# STM32U585 register map
File version: 1.4
CPU: CM33 r0p1, little endian, MPU, FPU, 4 interrupt priority bits
Registers are 32-bit, read-write, reset 0x0 unless marked. A register's access mark holds for its fields unless they carry their own. Offsets are from the block's base; [hi:lo] are bit positions; {n}, {i} and the like mark numbered series; 'fields as' and 'values as' point back to an identical list.

## RCC (part 3 of 3) — Reset and clock control
Base 0x46020C00
Same registers: SEC_RCC 0x56020C00
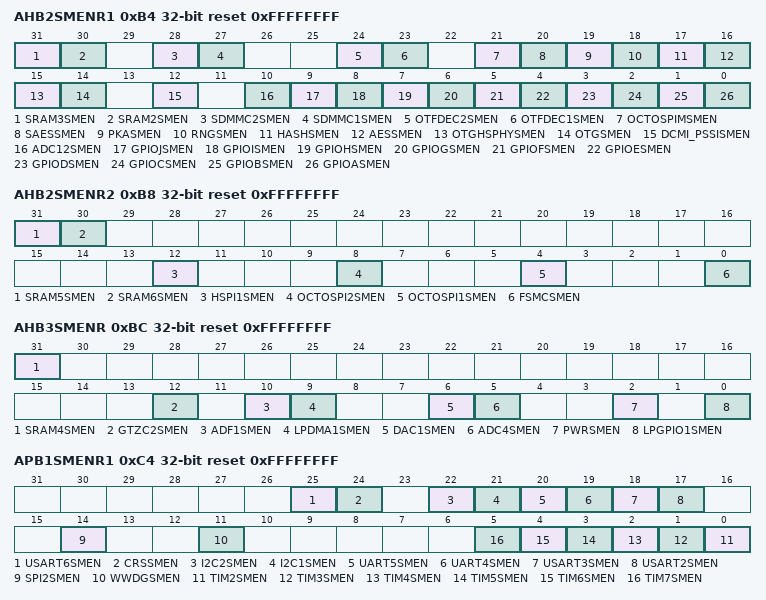
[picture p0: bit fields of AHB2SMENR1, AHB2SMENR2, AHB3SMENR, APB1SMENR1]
0xB4 AHB2SMENR1 reset 0xFFFFFFFF — RCC AHB2 peripheral clock enable in Sleep and Stop modes register 1
  [all] fields
    0=Disabled (Peripheral clocks disabled by the clock gating during Sleep and Stop modes); 1=Enabled (Peripheral clocks enabled by the clock gating during Sleep and Stop modes)
  [31] SRAM3SMEN — SRAM3 clock enable during Sleep and Stop modes This bit is set and cleared by software. Note: This bit is only available on some devices in the STM32U5 Series. Refer to the device datasheet for availability of its associated peripheral. If not present, consider this bit as reserved and keep it at reset value.
  [30] SRAM2SMEN — SRAM2 clock enable during Sleep and Stop modes This bit is set and cleared by software.
  [28] SDMMC2SMEN — SDMMC2 clock enable during Sleep and Stop modes This bit is set and cleared by software. Note: This bit is only available on some devices in the STM32U5 Series. Refer to the device datasheet for availability of its associated peripheral. If not present, consider this bit as reserved and keep it at reset value.
  [27] SDMMC1SMEN — SDMMC1 clock enable during Sleep and Stop modes This bit is set and cleared by software.
  [24] OTFDEC2SMEN — OTFDEC2 clock enable during Sleep and Stop modes This bit is set and cleared by software. Note: This bit is only available on some devices in the STM32U5 Series. Refer to the device datasheet for availability of its associated peripheral. If not present, consider this bit as reserved and keep it at reset value.
  [23] OTFDEC1SMEN — OTFDEC1 clock enable during Sleep and Stop modes This bit is set and cleared by software. Note: This bit is only available on some devices in the STM32U5 Series. Refer to the device datasheet for availability of its associated peripheral. If not present, consider this bit as reserved and keep it at reset value.
  [21] OCTOSPIMSMEN — OCTOSPIM clock enable during Sleep and Stop modes This bit is set and cleared by software. Note: This bit is only available on some devices in the STM32U5 Series. Refer to the device datasheet for availability of its associated peripheral. If not present, consider this bit as reserved and keep it at reset value.
  [20] SAESSMEN — SAES accelerator clock enable during Sleep and Stop modes This bit is set and cleared by software. Note: This bit is only available on some devices in the STM32U5 Series. Refer to the device datasheet for availability of its associated peripheral. If not present, consider this bit as reserved and keep it at reset value.
  [19] PKASMEN — PKA clock enable during Sleep and Stop modes This bit is set and cleared by software. Note: This bit is only available on some devices in the STM32U5 Series. Refer to the device datasheet for availability of its associated peripheral. If not present, consider this bit as reserved and keep it at reset value.
  [18] RNGSMEN — RNG clock enable during Sleep and Stop modes This bit is set and cleared by software.
  [17] HASHSMEN — HASH clock enable during Sleep and Stop modes This bit is set and cleared by software
  [16] AESSMEN — AES clock enable during Sleep and Stop modes This bit is set and cleared by software Note: This bit is only available on some devices in the STM32U5 Series. Refer to the device datasheet for availability of its associated peripheral. If not present, consider this bit as reserved and keep it at reset value.
  [15] OTGHSPHYSMEN — OTG_HS PHY clock enable during Sleep and Stop modes This bit is set and cleared by software Note: This bit is only available on some devices in the STM32U5 Series. Refer to the device datasheet for availability of its associated peripheral. If not present, consider this bit as reserved and keep it at reset value.
  [14] OTGSMEN — OTG_FS and OTG_HS clocks enable during Sleep and Stop modes This bit is set and cleared by software. Note: This bit is only available on some devices in the STM32U5 Series. Refer to the device datasheet for availability of its associated peripheral. If not present, consider this bit as reserved and keep it at reset value.
  [12] DCMI_PSSISMEN — DCMI and PSSI clock enable during Sleep and Stop modes This bit is set and cleared by software.
  [10] ADC12SMEN — ADC1 and ADC2 clock enable during Sleep and Stop modes This bit is set and cleared by software. Note: This bit impacts ADC1 in STM32U535/545/575/585 and ADC1/ADC2 in�STM32U59x/5Ax/5Fx/5Gx.
  [9] GPIOJSMEN — I/O port J clock enable during Sleep and Stop modes This bit is set and cleared by software. Note: This bit is only available on some devices in the STM32U5 Series. Refer to the device datasheet for availability of its associated peripheral. If not present, consider this bit as reserved and keep it at reset value.
  [8] GPIOISMEN — I/O port I clocks enable during Sleep and Stop modes This bit is set and cleared by software. Note: This bit is only available on some devices in the STM32U5 Series. Refer to the device datasheet for availability of its associated peripheral. If not present, consider this bit as reserved and keep it at reset value.
  [7] GPIOHSMEN — I/O port H clocks enable during Sleep and Stop modes This bit is set and cleared by software.
  [6] GPIOGSMEN — I/O port G clocks enable during Sleep and Stop modes This bit is set and cleared by software.
  [5] GPIOFSMEN — I/O port F clocks enable during Sleep and Stop modes This bit is set and cleared by software. Note: This bit is only available on some devices in the STM32U5 Series. Refer to the device datasheet for availability of its associated peripheral. If not present, consider this bit as reserved and keep it at reset value.
  [4] GPIOESMEN — I/O port E clocks enable during Sleep and Stop modes This bit is set and cleared by software.
  [3] GPIODSMEN — I/O port D clocks enable during Sleep and Stop modes This bit is set and cleared by software.
  [2] GPIOCSMEN — I/O port C clocks enable during Sleep and Stop modes This bit is set and cleared by software.
  [1] GPIOBSMEN — I/O port B clocks enable during Sleep and Stop modes This bit is set and cleared by software.
  [0] GPIOASMEN — I/O port A clocks enable during Sleep and Stop modes This bit is set and cleared by software.
0xB8 AHB2SMENR2 reset 0xFFFFFFFF — RCC AHB2 peripheral clock enable in Sleep and Stop modes register 2
  [all] fields
    values as the fields of AHB2SMENR1
  [31] SRAM5SMEN — SRAM5 clock enable during Sleep and Stop modes This bit is set and cleared by software. Note: This bit is only available on some devices in the STM32U5 Series. Refer to the device datasheet for availability of its associated peripheral. If not present, consider this bit as reserved and keep it at reset value.
  [30] SRAM6SMEN — SRAM6 clock enable during Sleep and Stop modes This bit is set and cleared by software. Note: This bit is only available on some devices in the STM32U5 Series. Refer to the device datasheet for availability of its associated peripheral. If not present, consider this bit as reserved and keep it at reset value.
  [12] HSPI1SMEN — HSPI1 clock enable during Sleep and Stop modes This bit is set and cleared by software. Note: This bit is only available on some devices in the STM32U5 Series. Refer to the device datasheet for availability of its associated peripheral. If not present, consider this bit as reserved and keep it at reset value.
  [8] OCTOSPI2SMEN — OCTOSPI2 clock enable during Sleep and Stop modes This bit is set and cleared by software. Note: This bit is only available on some devices in the STM32U5 Series. Refer to the device datasheet for availability of its associated peripheral. If not present, consider this bit as reserved and keep it at reset value.
  [4] OCTOSPI1SMEN — OCTOSPI1 clock enable during Sleep and Stop modes This bit is set and cleared by software.
  [0] FSMCSMEN — FSMC clock enable during Sleep and Stop modes This bit is set and cleared by software. Note: This bit is only available on some devices in the STM32U5 Series. Refer to the device datasheet for availability of its associated peripheral. If not present, consider this bit as reserved and keep it at reset value.
0xBC AHB3SMENR reset 0xFFFFFFFF — RCC AHB3 peripheral clock enable in Sleep and Stop modes register
  [all] fields
    values as the fields of AHB2SMENR1
  [31] SRAM4SMEN — SRAM4 clock enable during Sleep and Stop modes This bit is set and cleared by software.
  [12] GTZC2SMEN — GTZC2 clock enable during Sleep and Stop modes This bit is set and cleared by software.
  [10] ADF1SMEN — ADF1 clock enable during Sleep and Stop modes This bit is set and cleared by software. Note: This bit must be set to allow the peripheral to wake up from Stop modes.
  [9] LPDMA1SMEN — LPDMA1 clock enable during Sleep and Stop modes This bit is set and cleared by software. Note: This bit must be set to allow the peripheral to wake up from Stop modes.
  [6] DAC1SMEN — DAC1 clock enable during Sleep and Stop modes This bit is set and cleared by software. Note: This bit must be set to allow the peripheral to wake up from Stop modes.
  [5] ADC4SMEN — ADC4 clock enable during Sleep and Stop modes This bit is set and cleared by software. Note: This bit must be set to allow the peripheral to wake up from Stop modes.
  [2] PWRSMEN — PWR clock enable during Sleep and Stop modes This bit is set and cleared by software.
  [0] LPGPIO1SMEN — LPGPIO1 enable during Sleep and Stop modes This bit is set and cleared by software.
0xC4 APB1SMENR1 reset 0xFFFFFFFF — RCC APB1 peripheral clock enable in Sleep and Stop modes register 1
  [all] fields
    values as the fields of AHB2SMENR1
  [25] USART6SMEN — USART6 clock enable during Sleep and Stop modes This bit is set and cleared by software. Note: This bit must be set to allow the peripheral to wake up from Stop modes. Note: This bit is only available on some devices in the STM32U5 Series. Refer to the device datasheet for availability of its associated peripheral. If not present, consider this bit as reserved and keep it at reset value.
  [24] CRSSMEN — CRS clock enable during Sleep and Stop modes This bit is set and cleared by software.
  [22] I2C2SMEN — I2C2 clock enable during Sleep and Stop modes This bit is set and cleared by software. Note: This bit must be set to allow the peripheral to wake up from Stop modes.
  [21] I2C1SMEN — I2C1 clock enable during Sleep and Stop modes This bit is set and cleared by software. Note: This bit must be set to allow the peripheral to wake up from Stop modes.
  [20] UART5SMEN — UART5 clock enable during Sleep and Stop modes This bit is set and cleared by software. Note: This bit must be set to allow the peripheral to wake up from Stop modes.
  [19] UART4SMEN — UART4 clock enable during Sleep and Stop modes This bit is set and cleared by software. Note: This bit must be set to allow the peripheral to wake up from Stop modes.
  [18] USART3SMEN — USART3 clock enable during Sleep and Stop modes This bit is set and cleared by software. Note: This bit must be set to allow the peripheral to wake up from Stop modes.
  [17] USART2SMEN — USART2 clock enable during Sleep and Stop modes This bit is set and cleared by software. Note: This bit must be set to allow the peripheral to wake up from Stop modes. Note: This bit is only available on some devices in the STM32U5 Series. Refer to the device datasheet for availability of its associated peripheral. If not present, consider this bit as reserved and keep it at reset value.
  [14] SPI2SMEN — SPI2 clock enable during Sleep and Stop modes This bit is set and cleared by software. Note: This bit must be set to allow the peripheral to wake up from Stop modes.
  [11] WWDGSMEN — Window watchdog clock enable during Sleep and Stop modes This bit is set and cleared by software. It is forced to one by hardware when the hardware WWDG option is activated.
  [n-2] TIM{n}SMEN (n=2..7) — TIM{n} clock enable during Sleep and Stop modes This bit is set and cleared by software.
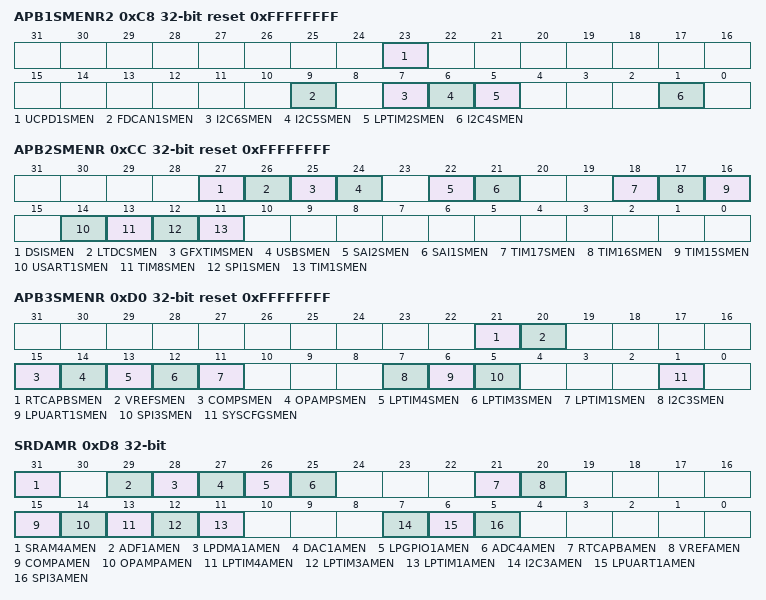
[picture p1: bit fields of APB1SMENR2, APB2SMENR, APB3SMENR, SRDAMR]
0xC8 APB1SMENR2 reset 0xFFFFFFFF — RCC APB1 peripheral clocks enable in Sleep and Stop modes register 2
  [all] fields
    values as the fields of AHB2SMENR1
  [23] UCPD1SMEN — UCPD1 clock enable during Sleep and Stop modes This bit is set and cleared by software. Note: This bit is only available on some devices in the STM32U5 Series. Refer to the device datasheet for availability of its associated peripheral. If not present, consider this bit as reserved and keep it at reset value.
  [9] FDCAN1SMEN — FDCAN1 clock enable during Sleep and Stop modes This bit is set and cleared by software.
  [7] I2C6SMEN — I2C6 clock enable during Sleep and Stop modes This bit is set and cleared by software Note: This bit must be set to allow the peripheral to wake up from Stop modes. Note: This bit is only available on some devices in the STM32U5 Series. Refer to the device datasheet for availability of its associated peripheral. If not present, consider this bit as reserved and keep it at reset value.
  [6] I2C5SMEN — I2C5 clock enable during Sleep and Stop modes This bit is set and cleared by software Note: This bit must be set to allow the peripheral to wake up from Stop modes. Note: This bit is only available on some devices in the STM32U5 Series. Refer to the device datasheet for availability of its associated peripheral. If not present, consider this bit as reserved and keep it at reset value.
  [5] LPTIM2SMEN — LPTIM2 clock enable during Sleep and Stop modes This bit is set and cleared by software. Note: This bit must be set to allow the peripheral to wake up from Stop modes.
  [1] I2C4SMEN — I2C4 clock enable during Sleep and Stop modes This bit is set and cleared by software Note: This bit must be set to allow the peripheral to wake up from Stop modes.
0xCC APB2SMENR reset 0xFFFFFFFF — RCC APB2 peripheral clocks enable in Sleep and Stop modes register
  [all] fields
    values as the fields of AHB2SMENR1
  [27] DSISMEN — DSI clock enable during Sleep and Stop modes This bit is set and cleared by software. Note: This bit is only available on some devices in the STM32U5 Series. Refer to the device datasheet for availability of its associated peripheral. If not present, consider this bit as reserved and keep it at reset value.
  [26] LTDCSMEN — LTDC clock enable during Sleep and Stop modes This bit is set and cleared by software. Note: This bit is only available on some devices in the STM32U5 Series. Refer to the device datasheet for availability of its associated peripheral. If not present, consider this bit as reserved and keep it at reset value.
  [25] GFXTIMSMEN — GFXTIM clock enable during Sleep and Stop modes This bit is set and cleared by software. Note: This bit is only available on some devices in the STM32U5 Series. Refer to the device datasheet for availability of its associated peripheral. If not present, consider this bit as reserved and keep it at reset value.
  [24] USBSMEN — USB clock enable during Sleep and Stop modes This bit is set and cleared by software. Note: This bit is only available on some devices in the STM32U5 Series. Refer to the device datasheet for availability of its associated peripheral. If not present, consider this bit as reserved and keep it at reset value.
  [22] SAI2SMEN — SAI2 clock enable during Sleep and Stop modes This bit is set and cleared by software. Note: This bit is only available on some devices in the STM32U5 Series.Refer to the device datasheet for availability of its associated peripheral. If not present, consider this bit as reserved and keep it at reset value.
  [21] SAI1SMEN — SAI1 clock enable during Sleep and Stop modes This bit is set and cleared by software.
  [18] TIM17SMEN — TIM17 clock enable during Sleep and Stop modes This bit is set and cleared by software.
  [17] TIM16SMEN — TIM16 clock enable during Sleep and Stop modes This bit is set and cleared by software.
  [16] TIM15SMEN — TIM15 clock enable during Sleep and Stop modes This bit is set and cleared by software.
  [14] USART1SMEN — USART1 clock enable during Sleep and Stop modes This bit is set and cleared by software. Note: This bit must be set to allow the peripheral to wake up from Stop modes.
  [13] TIM8SMEN — TIM8 clock enable during Sleep and Stop modes This bit is set and cleared by software.
  [12] SPI1SMEN — SPI1 clock enable during Sleep and Stop modes This bit is set and cleared by software. Note: This bit must be set to allow the peripheral to wake up from Stop modes.
  [11] TIM1SMEN — TIM1 clock enable during Sleep and Stop modes This bit is set and cleared by software.
0xD0 APB3SMENR reset 0xFFFFFFFF — RCC APB3 peripheral clock enable in Sleep and Stop modes register
  [all] fields
    values as the fields of AHB2SMENR1
  [21] RTCAPBSMEN — RTC and TAMP APB clock enable during Sleep and Stop modes This bit is set and cleared by software. Note: This bit must be set to allow the peripheral to wake up from Stop modes.
  [20] VREFSMEN — VREFBUF clock enable during Sleep and Stop modes This bit is set and cleared by software.
  [15] COMPSMEN — COMP clock enable during Sleep and Stop modes This bit is set and cleared by software.
  [14] OPAMPSMEN — OPAMP clock enable during Sleep and Stop modes This bit is set and cleared by software.
  [13] LPTIM4SMEN — LPTIM4 clock enable during Sleep and Stop modes This bit is set and cleared by software. Note: This bit must be set to allow the peripheral to wake up from Stop modes.
  [12] LPTIM3SMEN — LPTIM3 clock enable during Sleep and Stop modes This bit is set and cleared by software. Note: This bit must be set to allow the peripheral to wake up from Stop modes.
  [11] LPTIM1SMEN — LPTIM1 clock enable during Sleep and Stop modes This bit is set and cleared by software. Note: This bit must be set to allow the peripheral to wake up from Stop modes.
  [7] I2C3SMEN — I2C3 clock enable during Sleep and Stop modes This bit is set and cleared by software. Note: This bit must be set to allow the peripheral to wake up from Stop modes.
  [6] LPUART1SMEN — LPUART1 clock enable during Sleep and Stop modes This bit is set and cleared by software. Note: This bit must be set to allow the peripheral to wake up from Stop modes.
  [5] SPI3SMEN — SPI3 clock enable during Sleep and Stop modes This bit is set and cleared by software. Note: This bit must be set to allow the peripheral to wake up from Stop modes.
  [1] SYSCFGSMEN — SYSCFG clock enable during Sleep and Stop modes This bit is set and cleared by software.
0xD8 SRDAMR — RCC SmartRun domain peripheral autonomous mode register
  [all] fields
    0=Disabled (Peripheral autonomous mode disabled during Stop 0/1/2 mode); 1=Enabled (Peripheral autonomous mode enabled during Stop 0/1/2 mode)
  [31] SRAM4AMEN — SRAM4 autonomous mode enable in Stop 0/1/2 mode This bit is set and cleared by software.
  [29] ADF1AMEN — ADF1 autonomous mode enable in Stop 0/1/2 mode This bit is set and cleared by software. Note: This bit must be set to allow the peripheral to wake up from Stop modes.
  [28] LPDMA1AMEN — LPDMA1 autonomous mode enable in Stop 0/1/2 mode This bit is set and cleared by software. Note: This bit must be set to allow the peripheral to wake up from Stop modes.
  [27] DAC1AMEN — DAC1 autonomous mode enable in Stop 0/1/2 mode This bit is set and cleared by software. Note: This bit must be set to allow the peripheral to wake up from Stop modes.
  [26] LPGPIO1AMEN — LPGPIO1 autonomous mode enable in Stop 0/1/2 mode This bit is set and cleared by software.
  [25] ADC4AMEN — ADC4 autonomous mode enable in Stop 0/1/2 mode This bit is set and cleared by software. Note: This bit must be set to allow the peripheral to wake up from Stop modes.
  [21] RTCAPBAMEN — RTC and TAMP autonomous mode enable in Stop 0/1/2 mode This bit is set and cleared by software. Note: This bit must be set to allow the peripheral to wake up from Stop modes.
  [20] VREFAMEN — VREFBUF autonomous mode enable in Stop 0/1/2 mode This bit is set and cleared by software.
  [15] COMPAMEN — COMP autonomous mode enable in Stop 0/1/2 mode This bit is set and cleared by software.
  [14] OPAMPAMEN — OPAMP autonomous mode enable in Stop 0/1/2 mode This bit is set and cleared by software.
  [13] LPTIM4AMEN — LPTIM4 autonomous mode enable in Stop 0/1/2 mode This bit is set and cleared by software. Note: This bit must be set to allow the peripheral to wake up from Stop modes.
  [12] LPTIM3AMEN — LPTIM3 autonomous mode enable in Stop 0/1/2 mode This bit is set and cleared by software. Note: This bit must be set to allow the peripheral to wake up from Stop modes.
  [11] LPTIM1AMEN — LPTIM1 autonomous mode enable in Stop 0/1/2 mode This bit is set and cleared by software. Note: This bit must be set to allow the peripheral to wake up from Stop modes.
  [7] I2C3AMEN — I2C3 autonomous mode enable in Stop 0/1/2 mode This bit is set and cleared by software. Note: This bit must be set to allow the peripheral to wake up from Stop modes.
  [6] LPUART1AMEN — LPUART1 autonomous mode enable in Stop 0/1/2 mode This bit is set and cleared by software. Note: This bit must be set to allow the peripheral to wake up from Stop modes.
  [5] SPI3AMEN — SPI3 autonomous mode enable in Stop 0,1, 2 mode This bit is set and cleared by software. Note: This bit must be set to allow the peripheral to wake up from Stop modes.
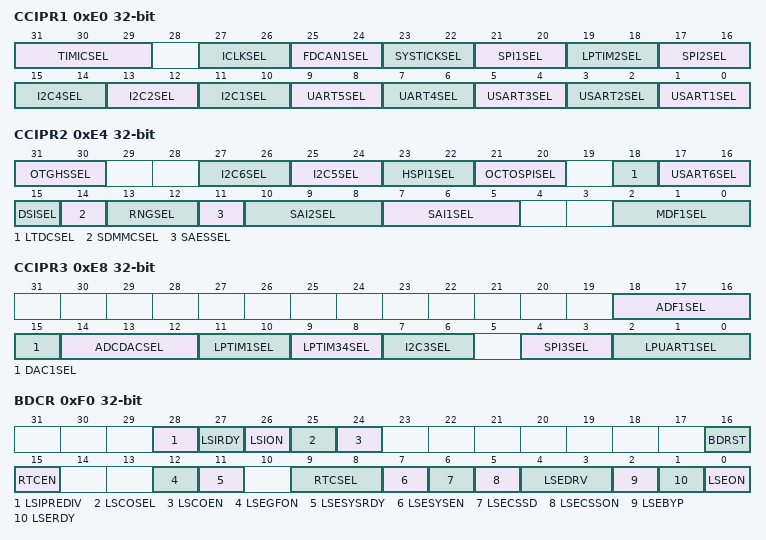
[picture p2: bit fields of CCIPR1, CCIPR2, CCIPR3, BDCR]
0xE0 CCIPR1 — RCC peripherals independent clock configuration register 1
  [31:29] TIMICSEL — Clock sources for TIM16,TIM17, and LPTIM2 internal input capture When TIMICSEL2 is set, the TIM16, TIM17, and LPTIM2 internal input capture can be connected either to HSI/256, MSI/4, or MSI/1024. Depending on TIMICSEL[1:0] value, MSI is either MSIK or MSIS. When TIMICSEL2 is cleared, the HSI, MSIK, and MSIS clock sources cannot be selected as�TIM16, TIM17, or LPTIM2 internal input capture. 0xx: HSI, MSIK and MSIS dividers disabled Note: The clock division must be disabled (TIMICSEL configured to 0xx) before selecting or changing a clock sources division.
    4=HsiMsisMsis (HSI/256, MSIS/1024 and MSIS/4 generated and can be selected by TIM16, TIM17, and LPTIM2 as internal input capture); 5=HsiMsisMsik (HSI/256, MSIS/1024 and MSIK/4 generated and can be selected by TIM16, TIM17, and LPTIM2 as internal input capture); 6=HsiMsikMsis (HSI/256, MSIK/1024 and MSIS/4 generated and can be selected by TIM16, TIM17, and LPTIM2 as internal input capture); 7=HsiMsikMsik (HSI/256, MSIK/1024 and MSIK/4 generated and can be selected by TIM16, TIM17, and LPTIM2 as internal input capture); other=Disabled (HSI, MSIK and MSIS dividers disabled)
  [27:26] ICLKSEL — Intermediate clock source selection These bits are used to select the clock source for the OTG_FS, the USB, and the SDMMC.
    0=HSI (HSI48 clock selected); 1=PLL2Q (PLL2 "Q" (pll2_q_ck) selected); 2=PLL1Q (PLL1 "Q" (pll1_q_ck) selected); 3=MSIK (MSIK clock selected)
  [25:24] FDCAN1SEL — FDCAN1 kernel clock source selection These bits are used to select the FDCAN1 kernel clock source.
    0=HSE (HSE clock selected); 1=PLL1Q (PLL1 "Q" (pll2_q_ck) selected); 2=PLL2P (PLL2 "P" (pll1_p_ck) selected)
  [23:22] SYSTICKSEL — SysTick clock source selection These bits are used to select the SysTick clock source. Note: When LSE or LSI is selected, the AHB frequency must be at least four times higher than the LSI or LSE frequency. In addition, a jitter up to one HCLK cycle is introduced, due to the LSE or LSI sampling with HCLK in the SysTick circuitry.
    0=HCLK_Div8 (HCLK/8 selected); 1=LSI (LSI selected); 2=LSE (LSE selected)
  [21:20] SPI1SEL — SPI1 kernel clock source selection These bits are used to select the SPI1 kernel clock source. Note: The SPI1 is functional in Stop 0 and Stop 1 mode only when the kernel clock is HSI16 or MSIK.
    0=PCLK (PCLKx selected); 1=SYSCLK (SYSCLK selected); 2=HSI16 (HSI16 selected); 3=MSIK (MSIK selected)
  [19:18] LPTIM2SEL — Low-power timer 2 kernel clock source selection These bits are used to select the LPTIM2 kernel clock source. Note: The LPTIM2 is functional in Stop 0 and Stop 1 mode only when the kernel clock is LSI, LSE or HSI16 if HSIKERON = 1.
    0=PCLK1 (PCLK1 selected); 1=LSI (LSI selected); 2=HSI16 (HSI16 selected); 3=MSIK (MSIK selected)
  [17:16] SPI2SEL — SPI2 kernel clock source selection These bits are used to select the SPI2 kernel clock source. Note: The SPI2 is functional in Stop 0 and Stop 1 mode only when the kernel clock is HSI16 or MSIK.
    values as SPI1SEL
  [15:14] I2C4SEL — I2C4 kernel clock source selection These bits are used to select the I2C4 kernel clock source. Note: The I2C4 is functional in Stop 0 and Stop 1 modes only when the kernel clock is HSI16�or MSIK.
    values as SPI1SEL
  [13:12] I2C2SEL — I2C2 kernel clock source selection These bits are used to select the I2C2 kernel clock source. Note: The I2C2 is functional in Stop 0 and Stop 1 mode sonly when the kernel clock is HSI16�or MSIK.
    values as SPI1SEL
  [11:10] I2C1SEL — I2C1 kernel clock source selection These bits are used to select the I2C1 kernel clock source. Note: The I2C1 is functional in Stop 0 and Stop 1 mode sonly when the kernel clock is HSI16�or MSIK.
    values as SPI1SEL
  [9:8] UART5SEL — UART5 kernel clock source selection These bits are used to select the UART5 kernel clock source. Note: The UART5 is functional in Stop 0 and Stop 1 modes only when the kernel clock is HSI16 or LSE.
    values as SPI1SEL
  [7:6] UART4SEL — UART4 kernel clock source selection These bits are used to select the UART4 kernel clock source. Note: The UART4 is functional in Stop 0 and Stop 1 modes only when the kernel clock is HSI16 or LSE.
    values as SPI1SEL
  [5:4] USART3SEL — USART3 kernel clock source selection These bits are used to select the USART3 kernel clock source. Note: The USART3 is functional in Stop 0 and Stop 1 modes only when the kernel clock is HSI16 or LSE.
    values as SPI1SEL
  [3:2] USART2SEL — USART2 kernel clock source selection These bits are used to select the USART2 kernel clock source. The USART2 is functional in Stop 0 and Stop 1 modes only when the kernel clock is HSI16 or LSE. Note: This bitfield is only available on some devices in the STM32U5 Series. Refer to the device datasheet for availability of its associated peripheral. If not present, consider this bitfield as reserved and keep it at reset value.
    values as SPI1SEL
  [1:0] USART1SEL — USART1 kernel clock source selection These bits are used to select the USART1 kernel clock source. Note: The USART1 is functional in Stop 0 and Stop 1 modes only when the kernel clock is HSI16 or LSE.
    values as SPI1SEL
0xE4 CCIPR2 — RCC peripherals independent clock configuration register 2
  [31:30] OTGHSSEL — OTG_HS PHY kernel clock source selection These bits are used to select the OTG_HS PHY kernel clock source. Note: This bitfield is only available on some devices in the STM32U5 Series. Refer to the device datasheet for availability of its associated peripheral. If not present, consider this bitfield as reserved and keep it at reset value.
    0=HSE (HSE selected); 1=PLL1P (PLL1 "Q" (pll1_q_ck) selected); 2=HSE2 (HSE/2 selected); 3=PLL1P_Div2 (PLL1 "P" divided by 2 (pll1_p_ck/2) selected)
  [27:26] I2C6SEL — I2C6 kernel clock source selection These bits are used to select the I2C6 kernel clock source. The I2C6 is functional in Stop 0 and Stop 1 modes only when the kernel clock is HSI16�or MSIK. Note: This bitfield is only available on some devices in the STM32U5 Series. Refer to the device datasheet for availability of its associated peripheral. If not present, consider this bitfield as reserved and keep it at reset value.
    0=PCLK1 (PCLK1 selected); 1=SYSCLK (SYSCLK selected); 2=HSI16 (HSI16 selected); 3=MSIK (MSIK selected)
  [25:24] I2C5SEL — I2C5 kernel clock source selection These bits are used to select the I2C5 kernel clock source. The I2C5 is functional in Stop 0 and Stop 1 modes only when the kernel clock is HSI16�or MSIK. Note: This bitfield is only available on some devices in the STM32U5 Series. Refer to the device datasheet for availability of its associated peripheral. If not present, consider this bitfield as reserved and keep it at reset value.
    values as I2C6SEL
  [23:22] HSPI1SEL — HSPI1 kernel clock source selection These bits are used to select the HSPI1 kernel clock source. Note: This bitfield is only available on some devices in the STM32U5 Series. Refer to the device datasheet for availability of its associated peripheral. If not present, consider this bitfield as reserved and keep it at reset value.
    0=SYSCLK (SYSCLK selected); 1=PLL1Q (PLL1 "Q" (pll1_q_ck) selected, can be up to 200 MHz); 2=PLL2Q (PLL2 "Q" (pll2_q_ck) selected, can be up to 200 MHz); 3=PLL3R (PLL3 "R" (pll3_r_ck) selected, can be up to 200 MHz)
  [21:20] OCTOSPISEL — OCTOSPI1 and OCTOSPI2 kernel clock source selection These bits are used to select the OCTOSPI1 and OCTOSPI2 kernel clock source.
    0=SYSCLK (SYSCLK selected); 1=MSIK (MSIK selected); 2=PLL1Q (PLL1 "Q" (pll1_q_ck) selected, can be up to 200 MHz); 3=PLL2Q (PLL2 "Q" (pll2_q_ck) selected, can be up to 200 MHz)
  [18] LTDCSEL — LTDC kernel clock source selection This bit is used to select the LTDC kernel clock source. Note: This bit is only available on some devices in the STM32U5 Series. Refer to the device datasheet for availability of its associated peripheral. If not present, consider this bit as reserved and keep it at reset value.
    0=PLL3R (PLL3 "R" (pll3_r_ck) selected); 1=PLL2R (PLL2 "R" (pll2_r_ck) selected)
  [17:16] USART6SEL — USART6 kernel clock source selection These bits are used to select the USART6 kernel clock source. The USART6 is functional in Stop 0 and Stop 1 modes only when the kernel clock is HSI16 or LSE. Note: This bitfield is only available on some devices in the STM32U5 Series. Refer to the device datasheet for availability of its associated peripheral. If not present, consider this bitfield as reserved and keep it at reset value.
    values as I2C6SEL
  [15] DSISEL — DSI kernel clock source selection This bit is used to select the DSI kernel clock source. This bit is only available on some devices in the STM32U5 Series. Refer to the device datasheet for availability of its associated peripheral. Note: If not present, consider this bit as reserved and keep it at reset value.
    0=PLL3P (PLL3 "P" (pll3_p_ck) selected); 1=DSI_PHY_PLL (DSI PHY PLL output selected)
  [14] SDMMCSEL — SDMMC1 and SDMMC2 kernel clock source selection This bit is used to select the SDMMC kernel clock source. It is recommended to change it only after reset and before enabling the SDMMC.
    0=ICLK (ICLK clock selected); 1=PLL1P (PLL1 "P" (pll1_p_ck) selected, in case higher than 48 MHz is needed (for SDR50 mode))
  [13:12] RNGSEL — RNG kernel clock source selection These bits are used to select the RNG kernel clock source.
    0=HSI48 (HSI48 clock selected); 1=HSI48_Div2 (HSI48 / 2 selected, can be used in range 4); 2=HSI16 (HSI16 selected)
  [11] SAESSEL — SAES kernel clock source selection This bit is used to select the SAES kernel clock source. Note: This bit is only available on some devices in the STM32U5 Series. Refer to the device datasheet for availability of its associated peripheral. If not present, consider this bit as reserved and keep it at reset value.
    0=SHSI (SHSI selected); 1=SHSI_Div2 (SHSI / 2 selected, can be used in range 4)
  [10:8] SAI2SEL — SAI2 kernel clock source selection These bits are used to select the SAI2 kernel clock source. others: reserved If the selected clock is the external clock and this clock is stopped, a switch to another clock is impossible. Note: This bitfield is only available on some devices in the STM32U5 Series. Refer to the device datasheet for availability of its associated peripheral. If not present, consider this bitfield as reserved and keep it at reset value.
    0=PLL2P (PLL2 "P" (pll2_p_ck) selected); 1=PLL3P (PLL3 "P" (pll3_p_ck) selected); 2=PLL1P (PLL1 "P" (pll1_p_ck) selected); 3=AUDIOCLK (input pin AUDIOCLK selected); 4=HSI16 (HSI16 clock selected)
  [7:5] SAI1SEL — SAI1 kernel clock source selection These bits are used to select the SAI1 kernel clock source. others: reserved Note: If the selected clock is the external clock and this clock is stopped, a switch to another clock is impossible.
    values as SAI2SEL
  [2:0] MDF1SEL — MDF1 kernel clock source selection These bits are used to select the MDF1 kernel clock source. others: reserved
    0=HCLK (HCLK selected); 1=PLL1P (PLL1 "P" (pll1_p_ck) selected); 2=PLL3Q (PLL3 "Q" (pll3_q_ck) selected); 3=AUDIOCLK (input pin AUDIOCLK selected); 4=MSIK (MSIK clock selected)
0xE8 CCIPR3 — RCC peripherals independent clock configuration register 3
  [18:16] ADF1SEL — ADF1 kernel clock source selection These bits are used to select the ADF1 kernel clock source. others: reserved Note: The ADF1 is functional in Stop 0, Stop 1, and Stop 2 modes only when the kernel clock is AUDIOCLK or MSIK.
    values as CCIPR2.MDF1SEL
  [15] DAC1SEL — DAC1 sample-and-hold clock source selection This bit is used to select the DAC1 sample-and-hold clock source.
    0=LSE (LSE selected); 1=LSI (LSI selected)
  [14:12] ADCDACSEL — ADC1, ADC2, ADC4 and DAC1 kernel clock source selection These bits are used to select the ADC1, ADC2, ADC4, and DAC1 kernel clock source. others: reserved Note: The ADC1, ADC2, ADC4, and DAC1 are functional in Stop 0, Stop 1, and Stop 2 modes only when the kernel clock is HSI16 or MSIK (only ADC4 and DAC1 are functional in�Stop 2 mode).
    0=HCLK (HCLK clock selected); 1=SYSCLK (SYSCLK selected); 2=PLL2R (PLL2 "R" (pll2_r_ck) selected); 3=HSE (HSE clock selected); 4=HSI16 (HSI16 clock selected); 5=MSIK (MSIK clock selected)
  [11:10] LPTIM1SEL — LPTIM1 kernel clock source selection These bits are used to select the LPTIM1 kernel clock source. Note: The LPTIM1 is functional in Stop 0, Stop 1, and Stop 2 modes only when the kernel clock is LSI, LSE, HSI16 with HSIKERON = 1, or MSIK with MSIKERON = 1.
    0=MSIK (MSIK clock selected); 1=LSI (LSI selected); 2=HSI16 (HSI16 selected); 3=LSE (LSE selected)
  [9:8] LPTIM34SEL — LPTIM3 and LPTIM4 kernel clock source selection These bits are used to select the LPTIM3 and LPTIM4 kernel clock source. Note: The LPTIM3 and LPTIM4 are functional in Stop 0, Stop 1, and Stop 2 modes only when the kernel clock is LSI, LSE, HSI16 with HSIKERON = 1, or MSIK with MSIKERON�=�1.
    0=MSIK (MSIK clock selected); 1=LSI (LSI selected); 2=HSI (HSI selected); 3=LSE (LSE selected)
  [7:6] I2C3SEL — I2C3 kernel clock source selection These bits are used to select the I2C3 kernel clock source. Note: The I2C3 is functional in Stop 0, Stop 1, and Stop 2 modes only when the kernel clock is HSI16 or MSIK.
    0=PCLK3 (PCLK3 selected); 1=SYSCLK (SYSCLK selected); 2=HSI16 (HSI16 selected); 3=MSIK (MSIK selected)
  [4:3] SPI3SEL — SPI3 kernel clock source selection These bits are used to select the SPI3 kernel clock source. Note: The SPI3 is functional in Stop 0, Stop 1, and Stop 2 modes only when the kernel clock is HSI16 or MSIK.
    values as I2C3SEL
  [2:0] LPUART1SEL — LPUART1 kernel clock source selection These bits are used to select the LPUART1 kernel clock source. others: reserved Note: The LPUART1 is functional in Stop 0, Stop 1, and Stop 2 modes only when the kernel clock is HSI16, LSE, or MSIK.
    0=PCLK3 (PCLK3 selected); 1=SYSCLK (SYSCLK selected); 2=HSI16 (HSI16 selected); 3=LSE (LSE selected); 4=MSIK (MSIK selected)
0xF0 BDCR access per field — RCC backup domain control register
  [28] LSIPREDIV rw — Low-speed clock divider configuration This bit is set and cleared by software to enable the LSI division. It can be written only when the LSI is disabled (LSION = 0 and LSIRDY = 0). If the LSI was previously enabled, it is necessary to wait for at least 60 μs after clearing LSION bit (synchronization time for LSI to be really disabled), before writing LSIPREDIV. The LSIPREDIV cannot be changed if the LSI is used by the IWDG or by the RTC.
    0=Div1 (LSI not divided); 1=Div128 (LSI divided by 128)
  [27] LSIRDY rw — LSI oscillator ready This bit is set and cleared by hardware to indicate when the LSI oscillator is stable. After�LSION is cleared, LSIRDY goes low after three internal low-speed oscillator clock cycles. This bit is set when the LSI is used by IWDG or RTC, even if LSION = 0.
    on read: 0=NotReady (LSI oscillator not ready); 1=Ready (LSI oscillator ready)
  [26] LSION rw — LSI oscillator enable This bit is set and cleared by software. The LSI oscillator is disabled 60��s maximum after the LSION bit is cleared.
    0=Disabled (LSI oscillator OFF); 1=Enabled (LSI oscillator ON)
  [25] LSCOSEL rw — Low-speed clock output selection This bit is set and cleared by software.
    0=LSI (LSI clock selected); 1=LSE (LSE clock selected)
  [24] LSCOEN rw — Low-speed clock output (LSCO) enable This bit is set and cleared by software.
    0=Disabled (LSCO disabled); 1=Enabled (LSCO enabled)
  [16] BDRST rw — Backup domain software reset This bit is set and cleared by software.
    0=NoReset (Reset not activated); 1=Reset the entire backup domain
  [15] RTCEN rw — RTC and TAMP clock enable This bit is set and cleared by software.
    0=Disabled (RTC and TAMP clock disabled); 1=Enabled (RTC and TAMP clock enabled)
  [12] LSEGFON rw — LSE clock glitch filter enable This bit is set and cleared by hardware to enable the LSE glitch filter. It can be written only when the LSE is disabled (LSEON = 0 and LSERDY = 0).
    0=Disabled (LSE glitch filter disabled); 1=Enabled (LSE glitch filter enabled)
  [11] LSESYSRDY ro — LSE system clock (LSESYS) ready This bit is set and cleared by hardware to indicate when the LSE system clock is stable.When LSESYSEN is set, this LSESYSRDY flag is set after two LSE clock cycles. The LSE clock must be already enabled and stable (LSEON and LSERDY are set). When the LSEON bit is cleared, LSERDY goes low after six external low-speed oscillator clock cycles.
    0=NotReady (LSESYS clock not ready); 1=Ready (LSESYS clock ready)
  [9:8] RTCSEL rw — RTC and TAMP clock source selection This bit is set by software to select the clock source for the RTC and TAMP. Once the RTC and TAMP clock source has been selected, it cannot be changed anymore unless the�backup domain is reset, or unless a failure is detected on LSE (LSECSSD is set). BDRST bit can be used to reset them.
    0=No clock selected; 1=LSE (LSE oscillator clock selected); 2=LSI (LSI oscillator clock selected); 3=HSE_Div32 (HSE oscillator clock divided by 32 selected)
  [7] LSESYSEN rw — LSE system clock (LSESYS) enable This bit is set by software to enable always the LSE system clock generated by RCC, which can be used by any peripheral when its source clock is the LSE, or at system level if one of LSCOSEL, MCO, or MSI PLL mode is needed.
    0=Disabled (LSE can be used only for RTC, TAMP, and CSS on LSE); 1=Enabled (LSE can be used by any other peripheral or function)
  [6] LSECSSD ro — CSS on LSE failure detection This bit is set by hardware to indicate when a failure is detected by the CCS on the external 32�kHz oscillator (LSE).
    0=No failure detected on LSE; 1=Failure detected on LSE
  [5] LSECSSON rw — CSS on LSE enable This bit is set by software to enable the CSS on LSE. It must be enabled after the LSE oscillator is enabled (LSEON bit enabled) and ready (LSERDY flag set by hardware), and after the RTCSEL bit is selected. Once enabled, this bit cannot be disabled, except after a LSE failure detection (LSECSSD�=�1). In that case, the software must disable this LSECSSON bit.
    0=Disabled (CSS on LSE OFF); 1=Enabled (CSS on LSE ON)
  [4:3] LSEDRV rw — LSE oscillator drive capability This bitfield is set by software to modulate the drive capability of the LSE oscillator. It can be written only when the external 32 kHz oscillator is disabled (LSEON = 0 and LSERDY = 0). Note: The oscillator is in ‘Xtal mode’ when it is not in bypass mode.
    0=Lower ('Xtal mode' lower driving capability); 1=MediumLow ('Xtal mode' medium-low driving capability); 2=MediumHigh ('Xtal mode' medium-high driving capability); 3=Higher ('Xtal mode' higher driving capability)
  [2] LSEBYP rw — LSE oscillator bypass This bit is set and cleared by software to bypass oscillator in debug mode. It can be written only when the external 32�kHz oscillator is disabled (LSEON = 0 and LSERDY = 0).
    0=NotBypassed (LSE oscillator not bypassed); 1=Bypassed (LSE oscillator bypassed)
  [1] LSERDY ro — LSE oscillator ready This bit is set and cleared by hardware to indicate when the external 32�kHz oscillator is stable. After LSEON is cleared, this LSERDY bit goes low after six external low-speed oscillator clock cycles.
    0=NotReady (LSE oscillator not ready); 1=Ready (LSE oscillator ready)
  [0] LSEON rw — LSE oscillator enable This bit is set and cleared by software.
    0=Disabled (LSE oscillator off); 1=Enabled (LSE oscillator on)
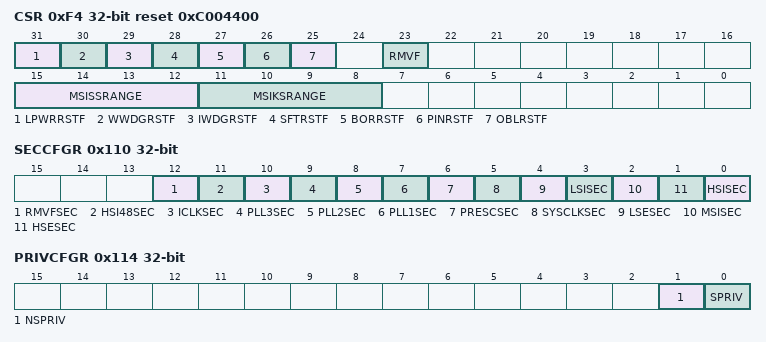
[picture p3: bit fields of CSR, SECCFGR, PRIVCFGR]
0xF4 CSR access per field reset 0xC004400 — RCC control/status register
  [31] LPWRRSTF ro — Low-power reset flag This bit is set by hardware when a reset occurs due to a Stop, Standby, or Shutdown mode entry, whereas the corresponding NRST_STOP, NRST_STBY, or NRST_SHDW option bit is cleared. This bit is cleared by writing to the RMVF bit.
    0=NotOccured (No illegal low-power mode reset occurred); 1=Occured (Illegal low-power mode reset occurred)
  [30] WWDGRSTF ro — Window watchdog reset flag This bit is set by hardware when a window watchdog reset occurs. It is cleared by writing to�the RMVF bit.
    0=NotOccured (No window watchdog reset occurred); 1=Occured (Window watchdog reset occurred)
  [29] IWDGRSTF ro — Independent watchdog reset flag This bit is set by hardware when an independent watchdog reset domain occurs. It is cleared by writing to the RMVF bit.
    0=NotOccured (No independent watchdog reset occurred); 1=Occured (Independent watchdog reset occurred)
  [28] SFTRSTF ro — Software reset flag This bit is set by hardware when a software reset occurs. It is cleared by writing to RMVF.
    0=NotOccured (No software reset occurred); 1=Occured (Software reset occurred)
  [27] BORRSTF ro — Brownout reset or an exit from Shutdown mode reset flag This bit is set by hardware when a brownout reset or an exit from Shutdown mode reset occurs. It is cleared by writing to the RMVF bit.
    0=NotOccured (No BOR/exit from Shutdown mode reset occurred); 1=Occured (BOR/exit from Shutdown mode reset occurred)
  [26] PINRSTF ro — NRST pin reset flag This bit is set by hardware when a reset from the NRST pin occurs. It is cleared by writing to�the RMVF bit.
    0=NotOccured (No reset from NRST pin occurred); 1=Occured (Reset from NRST pin occurred)
  [25] OBLRSTF ro — Option-byte loader reset flag This bit is set by hardware when a reset from the option-byte loading occurs. It is cleared by�writing to the RMVF bit.
    0=NotOccured (No reset from option-byte loading occurred); 1=Occured (Reset from option-byte loading occurred)
  [23] RMVF rw — Remove reset flag This bit is set by software to clear the reset flags.
    on write: 1=Clear the reset flags
  [15:12] MSISSRANGE rw — MSIS range after Standby mode This bitfield is set by software to chose the MSIS frequency at startup. It is used after exiting Standby mode until MSIRGSEL is set. After a NRST pin or a power-on reset or when exiting Shutdown mode, the range is always 4�MHz. MSISSRANGE can be written only when MSIRGSEL = 1. others: reserved Note: Changing this bitfield does not change the current MSIS frequency.
    4=f_4MHz (Range 4 around 4 MHz); 5=f_2MHz (Range 5 around 2 MHz); 6=f_1_33MHz (Range 6 around 1.33 MHz); 7=f_1MHz (Range 7 around 1 MHz); 8=f_3_072MHz (Range 8 around 3.072 MHz)
  [11:8] MSIKSRANGE rw — MSIK range after Standby mode This bit is set by software to chose the MSIK frequency at startup. It is used after exiting Standby mode until MSIRGSEL is set. After a NRST pin or a power-on reset or when exiting Shutdown mode, the range is always 4�MHz. MSIKSRANGE can be written only when MSIRGSEL = 1. others: reserved Note: Changing this bitfield does not change the current MSIK frequency.
    values as MSISSRANGE
0x110 SECCFGR — RCC secure configuration register
  [all] fields
    0=NonSecure; 1=Secure
  [12] RMVFSEC — Remove reset flag security This bit is set and reset by software.
  [11] HSI48SEC — HSI48 clock configuration and status bit security This bit is set and reset by software.
  [10] ICLKSEC — Intermediate clock source selection security This bit is set and reset by software.
  [9] PLL3SEC — PLL3 clock configuration and status bit security This bit is set and reset by software.
  [8] PLL2SEC — PLL2 clock configuration and status bit security Set and reset by software.
  [7] PLL1SEC — PLL1 clock configuration and status bit security This bit is set and reset by software.
  [6] PRESCSEC — AHBx/APBx prescaler configuration bits security This bit is set and reset by software.
  [5] SYSCLKSEC — SYSCLK clock selection, STOPWUCK bit, clock output on MCO configuration security This bit is set and reset by software.
  [4] LSESEC — LSE clock configuration and status bit security This bit is set and reset by software.
  [3] LSISEC — LSI clock configuration and status bit security This bit is set and reset by software.
  [2] MSISEC — MSI clock configuration and status bit security This bit is set and reset by software.
  [1] HSESEC — HSE clock configuration bits, status bit and HSE_CSS security This bit is set and reset by software.
  [0] HSISEC — HSI clock configuration and status bit security This bit is set and reset by software.
0x114 PRIVCFGR — RCC privilege configuration register
  [1] NSPRIV — RCC non-secure function privilege configuration This bit is set and reset by software. It can be written only by privileged access, secure or non-secure.
    0=Unprivileged (Read and write to RCC nonsecure functions can be done by privileged or unprivileged access); 1=Privileged (Read and write to RCC nonsecure functions can be done by privileged access only)
  [0] SPRIV — RCC secure function privilege configuration This bit is set and reset by software. It can be written only by a secure privileged access.
    0=Unprivileged (Read and write to RCC secure functions can be done by privileged or unprivileged access); 1=Privileged (Read and write to RCC secure functions can be done by privileged access only)
